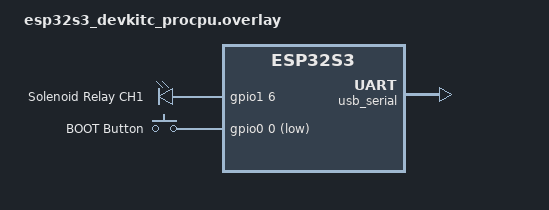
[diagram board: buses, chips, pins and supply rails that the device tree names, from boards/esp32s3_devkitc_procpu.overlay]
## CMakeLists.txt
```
cmake_minimum_required(VERSION 3.20.0)
find_package(Zephyr REQUIRED HINTS $ENV{ZEPHYR_BASE})
project(solenoid_test)

target_sources(app PRIVATE src/main.c)
```

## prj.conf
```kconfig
# solenoid_test prj.conf

CONFIG_PRINTK=y
CONFIG_CONSOLE=y
CONFIG_SERIAL=y

CONFIG_LOG=y
CONFIG_LOG_DEFAULT_LEVEL=3

CONFIG_GPIO=y
CONFIG_GPIO_INIT_PRIORITY=40

# main 栈给得宽裕一点，便于将来加按键中断 / shell
CONFIG_MAIN_STACK_SIZE=4096
```

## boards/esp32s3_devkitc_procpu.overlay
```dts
/* solenoid_test DTS overlay — ESP32-S3-BOX(-3) on esp32s3_devkitc/esp32s3/procpu
 *
 * 给 4路继电器模块的 IN1 一个 GPIO 输出。
 * 默认引脚：GPIO38（在 ESP32-S3-BOX-3 背部 PMOD-2 上可直接引出，
 * 也是 esp32s3_devkitc 排针上的常规可用 IO，不与 strapping 冲突）。
 *
 * 4路继电器模块通常是「低电平有效」（IN 拉低 → 触点闭合），
 * 因此用 GPIO_ACTIVE_LOW 标记，应用里 gpio_pin_set(1) 表示 ON。
 */

/ {
	chosen {
		zephyr,console = &usb_serial;
		zephyr,shell-uart = &usb_serial;
	};

	relays {
		compatible = "gpio-leds";
		relay0: relay0 {
			gpios = <&gpio1 6 GPIO_ACTIVE_HIGH>; /* GPIO38；本模块实测为高电平触发 */
			label = "Solenoid Relay CH1";
		};
	};

	buttons {
		compatible = "gpio-keys";
		boot_button: boot_button {
			gpios = <&gpio0 0 (GPIO_PULL_UP | GPIO_ACTIVE_LOW)>;
			label = "BOOT Button";
		};
	};

	aliases {
		sw0 = &boot_button;
		relay-fire = &relay0;
	};
};

&usb_serial {
	status = "okay";
};
```

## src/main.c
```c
/* solenoid_test main
 *
 * 行为：
 *   1) 启动后每 3 秒自动「开炮」一次：继电器 ON 80ms，OFF 2920ms。
 *   2) 按下 BOOT 按钮立刻「开炮」一次（手动单发）。
 *   3) 每次开炮在 USB 串口打印一行日志。
 *
 * 引脚：
 *   - relay-fire 别名 → GPIO38（ACTIVE_LOW，4路继电器 IN1）
 *   - sw0 别名 → GPIO0（BOOT 键，板载）
 */

#include <zephyr/kernel.h>
#include <zephyr/drivers/gpio.h>
#include <zephyr/logging/log.h>

LOG_MODULE_REGISTER(solenoid_test, LOG_LEVEL_INF);

#define PULSE_MS         80      /* 推杆通电时长，越短越省命越省 */
#define AUTO_PERIOD_MS   3000    /* 自动开炮周期 */

static const struct gpio_dt_spec relay =
	GPIO_DT_SPEC_GET(DT_ALIAS(relay_fire), gpios);
static const struct gpio_dt_spec button =
	GPIO_DT_SPEC_GET(DT_ALIAS(sw0), gpios);

static struct gpio_callback button_cb;
static struct k_work btn_fire_work;
static atomic_t fire_count = ATOMIC_INIT(0);

static void fire_once(const char *src)
{
	int n = atomic_inc(&fire_count) + 1;

	LOG_INF("FIRE #%d (%s, pulse=%dms)", n, src, PULSE_MS);
	gpio_pin_set_dt(&relay, 1);   /* ACTIVE_LOW: 1 = 拉低 = 继电器吸合 */
	k_msleep(PULSE_MS);
	gpio_pin_set_dt(&relay, 0);   /* 释放 */
}

static void btn_fire_handler(struct k_work *w)
{
	ARG_UNUSED(w);
	fire_once("button");
}

static void button_isr(const struct device *port,
		       struct gpio_callback *cb,
		       gpio_port_pins_t pins)
{
	ARG_UNUSED(port);
	ARG_UNUSED(cb);
	ARG_UNUSED(pins);
	/* 中断里不能 sleep，丢给 system workqueue */
	k_work_submit(&btn_fire_work);
}

int main(void)
{
	int ret;

	if (!gpio_is_ready_dt(&relay)) {
		LOG_ERR("relay gpio not ready");
		return -1;
	}
	if (!gpio_is_ready_dt(&button)) {
		LOG_ERR("button gpio not ready");
		return -1;
	}

	ret = gpio_pin_configure_dt(&relay, GPIO_OUTPUT_INACTIVE);
	if (ret) {
		LOG_ERR("relay configure failed: %d", ret);
		return ret;
	}

	ret = gpio_pin_configure_dt(&button, GPIO_INPUT);
	if (ret) {
		LOG_ERR("button configure failed: %d", ret);
		return ret;
	}

	ret = gpio_pin_interrupt_configure_dt(&button, GPIO_INT_EDGE_TO_ACTIVE);
	if (ret) {
		LOG_ERR("button interrupt configure failed: %d", ret);
		return ret;
	}

	k_work_init(&btn_fire_work, btn_fire_handler);
	gpio_init_callback(&button_cb, button_isr, BIT(button.pin));
	gpio_add_callback(button.port, &button_cb);

	LOG_INF("solenoid_test ready: relay=GPIO38 (ACTIVE_LOW), button=BOOT (GPIO0)");
	LOG_INF("auto-fire every %d ms, pulse=%d ms; press BOOT for manual shot",
		AUTO_PERIOD_MS, PULSE_MS);

	while (1) {
		k_msleep(AUTO_PERIOD_MS - PULSE_MS);
		fire_once("auto");
	}

	return 0;
}
```
